AUTOSAR XML (schema 4-3-0)
package /ComponentTypes
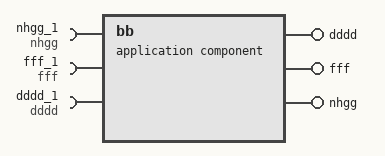
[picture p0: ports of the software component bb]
  application sw component type bb
    provide port dddd: provided-com-specs=[Element_1, Element], provided-interface=dddd
    provide port fff: provided-com-specs=[Element_1, Element], provided-interface=fff
    provide port nhgg: provided-com-specs=[{operation=rrth, queue-length=1}, {operation=hjn, queue-length=1}, {operation=Operation, queue-length=1}], provided-interface=nhgg
    require port nhgg_1: required-com-specs=[rrth, hjn, Operation], required-interface=nhgg
    require port fff_1: required-interface=fff
      required-com-specs:
        data-element=Element_1, filter=data-filter-type=ALWAYS
        data-element=Element, filter=data-filter-type=ALWAYS
    require port dddd_1: required-interface=dddd
      required-com-specs:
        data-element=Element_1, filter=data-filter-type=ALWAYS
        data-element=Element, filter=data-filter-type=ALWAYS
    behavior bb_InternalBehavior
  swc implementation bb_Implementation: behavior=bb_InternalBehavior
